# COMPUTE_CLUSTER0_C71SS0_ECC_AGGR_0_DSP0_ECC_AGGR register map
Vendor: Texas Instruments
Peripheral module from a debugger description file (folder J721S2).
Registers are 32-bit, access not given, reset 0x0 unless marked. A register's access mark holds for its fields unless they carry their own. Offsets are as the file gives them; lines under a group give offsets from that group; [hi:lo] are bit positions; {n}, {i} and the like mark numbered series; 'fields as' and 'values as' point back to an identical list; <NAME> marks a mode.

## COMPUTE_CLUSTER0_C71SS0_ECC_AGGR_0_DSP0_ECC_AGGR
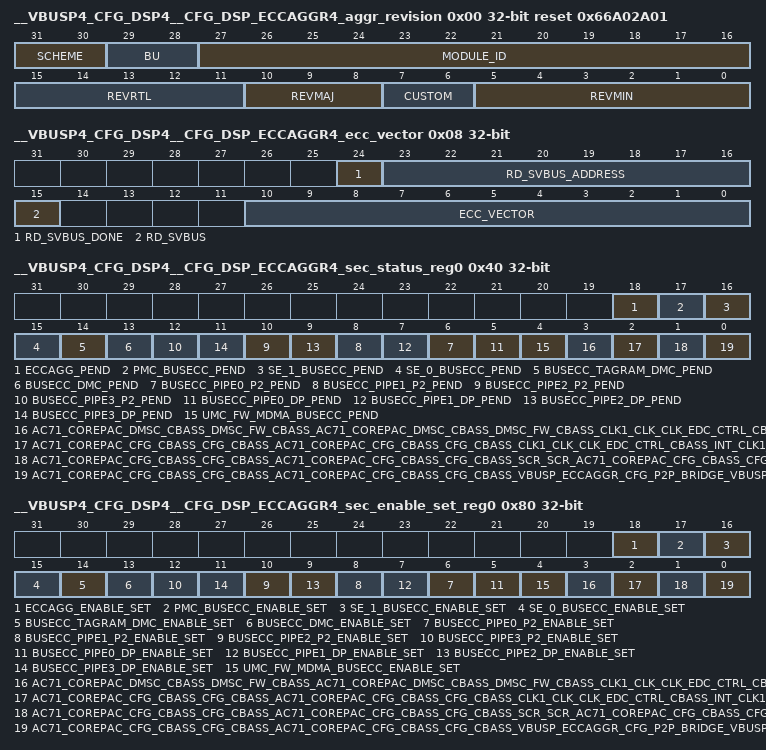
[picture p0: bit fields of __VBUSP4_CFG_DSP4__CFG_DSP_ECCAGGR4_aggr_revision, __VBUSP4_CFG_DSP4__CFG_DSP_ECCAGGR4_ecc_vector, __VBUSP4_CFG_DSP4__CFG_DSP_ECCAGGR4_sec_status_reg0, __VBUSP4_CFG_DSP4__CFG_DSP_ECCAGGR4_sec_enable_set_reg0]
0x00 __VBUSP4_CFG_DSP4__CFG_DSP_ECCAGGR4_aggr_revision ro reset 0x66A02A01 — Revision parameters
  [31:30] SCHEME
  [29:28] BU
  [27:16] MODULE_ID
  [15:11] REVRTL — RTL version
  [10:8] REVMAJ — Major version
  [7:6] CUSTOM — Custom version
  [5:0] REVMIN — Minor version
0x08 __VBUSP4_CFG_DSP4__CFG_DSP_ECCAGGR4_ecc_vector — ECC Vector Register
  [24] RD_SVBUS_DONE — Status to indicate if read on serial VBUS is complete, write of any value will clear this bit. (access R/W1TC)
  [23:16] RD_SVBUS_ADDRESS rw — Read address
  [15] RD_SVBUS — Write 1 to trigger a read on the serial VBUS (access R/W1TS)
  [10:0] ECC_VECTOR rw — Value written to select the corresponding ECC RAM for control or status
0x0C __VBUSP4_CFG_DSP4__CFG_DSP_ECCAGGR4_misc_status ro reset 0x13 — Misc Status
  [10:0] NUM_RAMS — Indicates the number of RAMS serviced by the ECC aggregator
0x10 __VBUSP4_CFG_DSP4__CFG_DSP_ECCAGGR4_reserved_svbus rw — Reference other documents that contain the ECC RAM wrapper and EDC controller serial vbus register sets.
  [31:0] DATA — Serial VBUS register data
0x3C __VBUSP4_CFG_DSP4__CFG_DSP_ECCAGGR4_sec_eoi_reg — EOI Register
  [0] EOI_WR — EOI Register (access R/W1TS)
0x40 __VBUSP4_CFG_DSP4__CFG_DSP_ECCAGGR4_sec_status_reg0 — Interrupt Status Register 0
  [18] ECCAGG_PEND — Interrupt Pending Status for eccagg_pend (access R/W1TS)
  [17] PMC_BUSECC_PEND — Interrupt Pending Status for pmc_busecc_pend (access R/W1TS)
  [16] SE_1_BUSECC_PEND — Interrupt Pending Status for se_1_busecc_pend (access R/W1TS)
  [15] SE_0_BUSECC_PEND — Interrupt Pending Status for se_0_busecc_pend (access R/W1TS)
  [14] BUSECC_TAGRAM_DMC_PEND — Interrupt Pending Status for busecc_tagram_dmc_pend (access R/W1TS)
  [13] BUSECC_DMC_PEND — Interrupt Pending Status for busecc_dmc_pend (access R/W1TS)
  [2n+6] BUSECC_PIPE{n}_P2_PEND (n=0..3) — Interrupt Pending Status for busecc_pipe{n}_p2_pend (access R/W1TS)
  [2n+5] BUSECC_PIPE{n}_DP_PEND (n=0..3) — Interrupt Pending Status for busecc_pipe{n}_dp_pend (access R/W1TS)
  [4] UMC_FW_MDMA_BUSECC_PEND — Interrupt Pending Status for umc_fw_mdma_busecc_pend (access R/W1TS)
  [3] AC71_COREPAC_DMSC_CBASS_DMSC_FW_CBASS_AC71_COREPAC_DMSC_CBASS_DMSC_FW_CBASS_CLK1_CLK_CLK_EDC_CTRL_CBASS_INT_CLK1_CLK_BUSECC_PEND — Interrupt Pending Status for ac71_corepac_dmsc_cbass_dmsc_fw_cbass_ac71_corepac_dmsc_cbass_dmsc_fw_cbass_clk1_clk_clk_edc_ctrl_cbass_int_clk1_clk_busecc_pend (access R/W1TS)
  [2] AC71_COREPAC_CFG_CBASS_CFG_CBASS_AC71_COREPAC_CFG_CBASS_CFG_CBASS_CLK1_CLK_CLK_EDC_CTRL_CBASS_INT_CLK1_CLK_BUSECC_PEND — Interrupt Pending Status for ac71_corepac_cfg_cbass_cfg_cbass_ac71_corepac_cfg_cbass_cfg_cbass_clk1_clk_clk_edc_ctrl_cbass_int_clk1_clk_busecc_pend (access R/W1TS)
  [1] AC71_COREPAC_CFG_CBASS_CFG_CBASS_AC71_COREPAC_CFG_CBASS_CFG_CBASS_SCR_SCR_AC71_COREPAC_CFG_CBASS_CFG_CBASS_SCR_SCR_EDC_CTRL_BUSECC_PEND — Interrupt Pending Status for ac71_corepac_cfg_cbass_cfg_cbass_ac71_corepac_cfg_cbass_cfg_cbass_scr_scr_ac71_corepac_cfg_cbass_cfg_cbass_scr_scr_edc_ctrl_busecc_pend (access R/W1TS)
  [0] AC71_COREPAC_CFG_CBASS_CFG_CBASS_AC71_COREPAC_CFG_CBASS_CFG_CBASS_VBUSP_ECCAGGR_CFG_P2P_BRIDGE_VBUSP_ECCAGGR_CFG_BRIDGE_BUSECC_PEND — Interrupt Pending Status for ac71_corepac_cfg_cbass_cfg_cbass_ac71_corepac_cfg_cbass_cfg_cbass_vbusp_eccaggr_cfg_p2p_bridge_vbusp_eccaggr_cfg_bridge_busecc_pend (access R/W1TS)
0x80 __VBUSP4_CFG_DSP4__CFG_DSP_ECCAGGR4_sec_enable_set_reg0 — Interrupt Enable Set Register 0
  [18] ECCAGG_ENABLE_SET — Interrupt Enable Set Register for eccagg_pend (access R/W1TS)
  [17] PMC_BUSECC_ENABLE_SET — Interrupt Enable Set Register for pmc_busecc_pend (access R/W1TS)
  [16] SE_1_BUSECC_ENABLE_SET — Interrupt Enable Set Register for se_1_busecc_pend (access R/W1TS)
  [15] SE_0_BUSECC_ENABLE_SET — Interrupt Enable Set Register for se_0_busecc_pend (access R/W1TS)
  [14] BUSECC_TAGRAM_DMC_ENABLE_SET — Interrupt Enable Set Register for busecc_tagram_dmc_pend (access R/W1TS)
  [13] BUSECC_DMC_ENABLE_SET — Interrupt Enable Set Register for busecc_dmc_pend (access R/W1TS)
  [2n+6] BUSECC_PIPE{n}_P2_ENABLE_SET (n=0..3) — Interrupt Enable Set Register for busecc_pipe{n}_p2_pend (access R/W1TS)
  [2n+5] BUSECC_PIPE{n}_DP_ENABLE_SET (n=0..3) — Interrupt Enable Set Register for busecc_pipe{n}_dp_pend (access R/W1TS)
  [4] UMC_FW_MDMA_BUSECC_ENABLE_SET — Interrupt Enable Set Register for umc_fw_mdma_busecc_pend (access R/W1TS)
  [3] AC71_COREPAC_DMSC_CBASS_DMSC_FW_CBASS_AC71_COREPAC_DMSC_CBASS_DMSC_FW_CBASS_CLK1_CLK_CLK_EDC_CTRL_CBASS_INT_CLK1_CLK_BUSECC_ENABLE_SET — Interrupt Enable Set Register for ac71_corepac_dmsc_cbass_dmsc_fw_cbass_ac71_corepac_dmsc_cbass_dmsc_fw_cbass_clk1_clk_clk_edc_ctrl_cbass_int_clk1_clk_busecc_pend (access R/W1TS)
  [2] AC71_COREPAC_CFG_CBASS_CFG_CBASS_AC71_COREPAC_CFG_CBASS_CFG_CBASS_CLK1_CLK_CLK_EDC_CTRL_CBASS_INT_CLK1_CLK_BUSECC_ENABLE_SET — Interrupt Enable Set Register for ac71_corepac_cfg_cbass_cfg_cbass_ac71_corepac_cfg_cbass_cfg_cbass_clk1_clk_clk_edc_ctrl_cbass_int_clk1_clk_busecc_pend (access R/W1TS)
  [1] AC71_COREPAC_CFG_CBASS_CFG_CBASS_AC71_COREPAC_CFG_CBASS_CFG_CBASS_SCR_SCR_AC71_COREPAC_CFG_CBASS_CFG_CBASS_SCR_SCR_EDC_CTRL_BUSECC_ENABLE_SET — Interrupt Enable Set Register for ac71_corepac_cfg_cbass_cfg_cbass_ac71_corepac_cfg_cbass_cfg_cbass_scr_scr_ac71_corepac_cfg_cbass_cfg_cbass_scr_scr_edc_ctrl_busecc_pend (access R/W1TS)
  [0] AC71_COREPAC_CFG_CBASS_CFG_CBASS_AC71_COREPAC_CFG_CBASS_CFG_CBASS_VBUSP_ECCAGGR_CFG_P2P_BRIDGE_VBUSP_ECCAGGR_CFG_BRIDGE_BUSECC_ENABLE_SET — Interrupt Enable Set Register for ac71_corepac_cfg_cbass_cfg_cbass_ac71_corepac_cfg_cbass_cfg_cbass_vbusp_eccaggr_cfg_p2p_bridge_vbusp_eccaggr_cfg_bridge_busecc_pend (access R/W1TS)
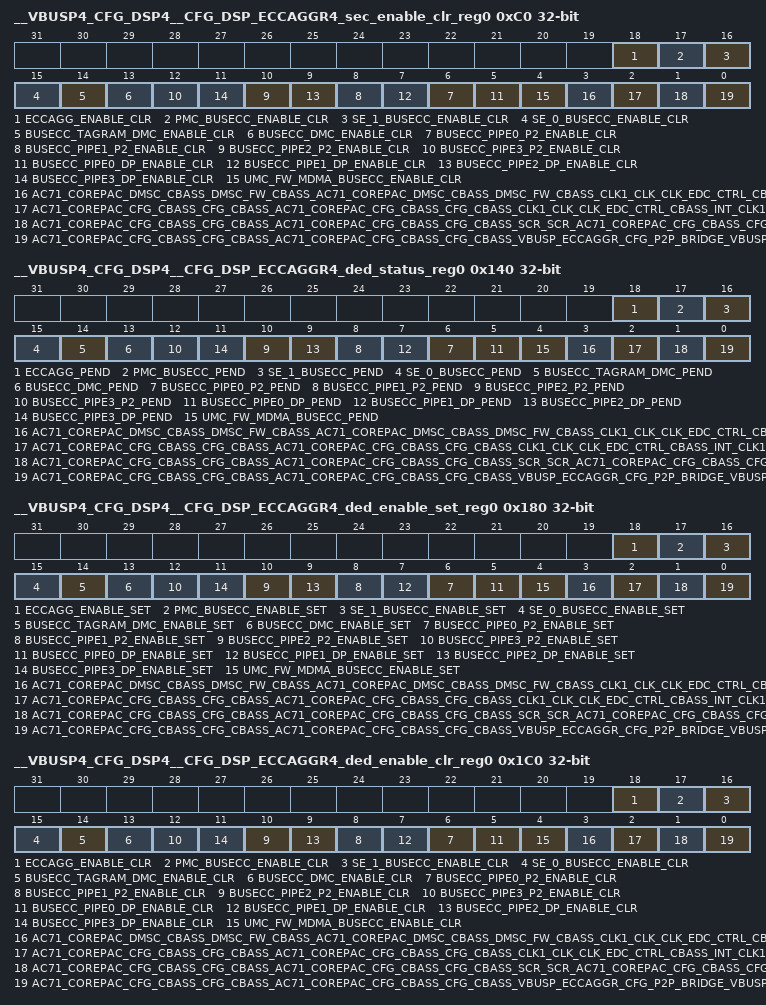
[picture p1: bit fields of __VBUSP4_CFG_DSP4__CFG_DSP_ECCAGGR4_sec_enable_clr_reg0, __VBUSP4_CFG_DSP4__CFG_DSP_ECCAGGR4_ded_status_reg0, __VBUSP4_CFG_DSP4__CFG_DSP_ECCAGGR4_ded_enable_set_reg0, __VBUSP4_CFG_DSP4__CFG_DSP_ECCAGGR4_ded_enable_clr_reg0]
0xC0 __VBUSP4_CFG_DSP4__CFG_DSP_ECCAGGR4_sec_enable_clr_reg0 — Interrupt Enable Clear Register 0
  [18] ECCAGG_ENABLE_CLR — Interrupt Enable Clear Register for eccagg_pend (access R/W1TC)
  [17] PMC_BUSECC_ENABLE_CLR — Interrupt Enable Clear Register for pmc_busecc_pend (access R/W1TC)
  [16] SE_1_BUSECC_ENABLE_CLR — Interrupt Enable Clear Register for se_1_busecc_pend (access R/W1TC)
  [15] SE_0_BUSECC_ENABLE_CLR — Interrupt Enable Clear Register for se_0_busecc_pend (access R/W1TC)
  [14] BUSECC_TAGRAM_DMC_ENABLE_CLR — Interrupt Enable Clear Register for busecc_tagram_dmc_pend (access R/W1TC)
  [13] BUSECC_DMC_ENABLE_CLR — Interrupt Enable Clear Register for busecc_dmc_pend (access R/W1TC)
  [2n+6] BUSECC_PIPE{n}_P2_ENABLE_CLR (n=0..3) — Interrupt Enable Clear Register for busecc_pipe{n}_p2_pend (access R/W1TC)
  [2n+5] BUSECC_PIPE{n}_DP_ENABLE_CLR (n=0..3) — Interrupt Enable Clear Register for busecc_pipe{n}_dp_pend (access R/W1TC)
  [4] UMC_FW_MDMA_BUSECC_ENABLE_CLR — Interrupt Enable Clear Register for umc_fw_mdma_busecc_pend (access R/W1TC)
  [3] AC71_COREPAC_DMSC_CBASS_DMSC_FW_CBASS_AC71_COREPAC_DMSC_CBASS_DMSC_FW_CBASS_CLK1_CLK_CLK_EDC_CTRL_CBASS_INT_CLK1_CLK_BUSECC_ENABLE_CLR — Interrupt Enable Clear Register for ac71_corepac_dmsc_cbass_dmsc_fw_cbass_ac71_corepac_dmsc_cbass_dmsc_fw_cbass_clk1_clk_clk_edc_ctrl_cbass_int_clk1_clk_busecc_pend (access R/W1TC)
  [2] AC71_COREPAC_CFG_CBASS_CFG_CBASS_AC71_COREPAC_CFG_CBASS_CFG_CBASS_CLK1_CLK_CLK_EDC_CTRL_CBASS_INT_CLK1_CLK_BUSECC_ENABLE_CLR — Interrupt Enable Clear Register for ac71_corepac_cfg_cbass_cfg_cbass_ac71_corepac_cfg_cbass_cfg_cbass_clk1_clk_clk_edc_ctrl_cbass_int_clk1_clk_busecc_pend (access R/W1TC)
  [1] AC71_COREPAC_CFG_CBASS_CFG_CBASS_AC71_COREPAC_CFG_CBASS_CFG_CBASS_SCR_SCR_AC71_COREPAC_CFG_CBASS_CFG_CBASS_SCR_SCR_EDC_CTRL_BUSECC_ENABLE_CLR — Interrupt Enable Clear Register for ac71_corepac_cfg_cbass_cfg_cbass_ac71_corepac_cfg_cbass_cfg_cbass_scr_scr_ac71_corepac_cfg_cbass_cfg_cbass_scr_scr_edc_ctrl_busecc_pend (access R/W1TC)
  [0] AC71_COREPAC_CFG_CBASS_CFG_CBASS_AC71_COREPAC_CFG_CBASS_CFG_CBASS_VBUSP_ECCAGGR_CFG_P2P_BRIDGE_VBUSP_ECCAGGR_CFG_BRIDGE_BUSECC_ENABLE_CLR — Interrupt Enable Clear Register for ac71_corepac_cfg_cbass_cfg_cbass_ac71_corepac_cfg_cbass_cfg_cbass_vbusp_eccaggr_cfg_p2p_bridge_vbusp_eccaggr_cfg_bridge_busecc_pend (access R/W1TC)
0x13C __VBUSP4_CFG_DSP4__CFG_DSP_ECCAGGR4_ded_eoi_reg — EOI Register
  [0] EOI_WR — EOI Register (access R/W1TS)
0x140 __VBUSP4_CFG_DSP4__CFG_DSP_ECCAGGR4_ded_status_reg0 — Interrupt Status Register 0
  fields as __VBUSP4_CFG_DSP4__CFG_DSP_ECCAGGR4_sec_status_reg0
0x180 __VBUSP4_CFG_DSP4__CFG_DSP_ECCAGGR4_ded_enable_set_reg0 — Interrupt Enable Set Register 0
  fields as __VBUSP4_CFG_DSP4__CFG_DSP_ECCAGGR4_sec_enable_set_reg0
0x1C0 __VBUSP4_CFG_DSP4__CFG_DSP_ECCAGGR4_ded_enable_clr_reg0 — Interrupt Enable Clear Register 0
  fields as __VBUSP4_CFG_DSP4__CFG_DSP_ECCAGGR4_sec_enable_clr_reg0
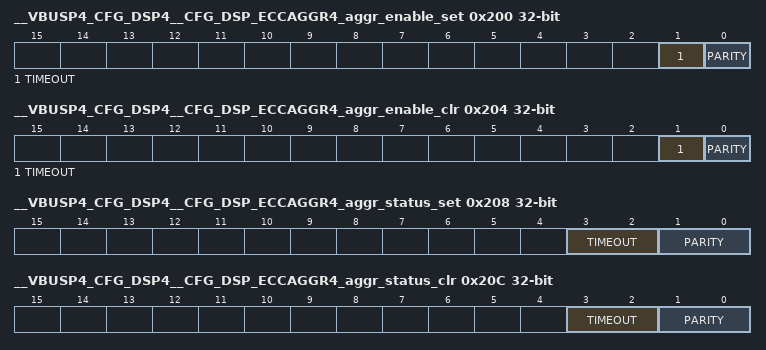
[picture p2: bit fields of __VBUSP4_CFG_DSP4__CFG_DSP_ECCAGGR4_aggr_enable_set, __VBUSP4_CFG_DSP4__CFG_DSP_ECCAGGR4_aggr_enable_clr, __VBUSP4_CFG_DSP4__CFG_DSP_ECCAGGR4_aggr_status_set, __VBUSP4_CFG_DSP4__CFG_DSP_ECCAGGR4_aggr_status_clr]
0x200 __VBUSP4_CFG_DSP4__CFG_DSP_ECCAGGR4_aggr_enable_set — AGGR interrupt enable set Register
  [1] TIMEOUT — interrupt enable set for svbus timeout errors (access R/W1TS)
  [0] PARITY — interrupt enable set for parity errors (access R/W1TS)
0x204 __VBUSP4_CFG_DSP4__CFG_DSP_ECCAGGR4_aggr_enable_clr — AGGR interrupt enable clear Register
  [1] TIMEOUT — interrupt enable clear for svbus timeout errors (access R/W1TC)
  [0] PARITY — interrupt enable clear for parity errors (access R/W1TC)
0x208 __VBUSP4_CFG_DSP4__CFG_DSP_ECCAGGR4_aggr_status_set — AGGR interrupt status set Register
  [3:2] TIMEOUT — interrupt status set for svbus timeout errors (access R/WI)
  [1:0] PARITY — interrupt status set for parity errors (access R/WI)
0x20C __VBUSP4_CFG_DSP4__CFG_DSP_ECCAGGR4_aggr_status_clr — AGGR interrupt status clear Register
  [3:2] TIMEOUT — interrupt status clear for svbus timeout errors (access R/WD)
  [1:0] PARITY — interrupt status clear for parity errors (access R/WD)
